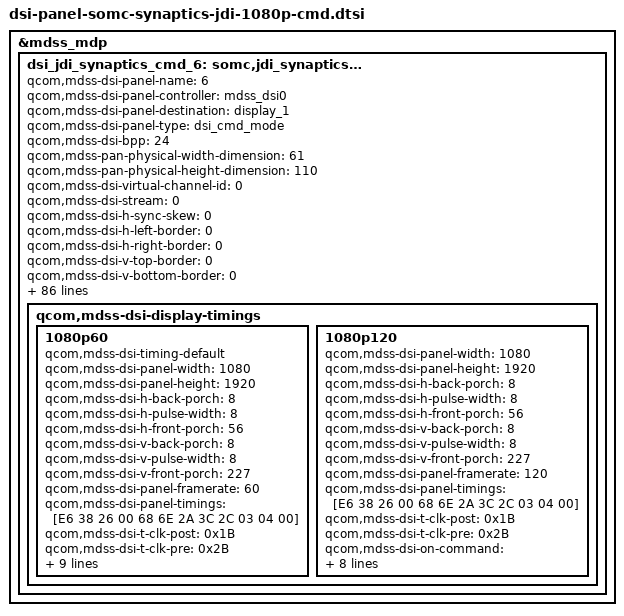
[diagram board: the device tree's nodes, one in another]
/* Copyright (c) 2016, The Linux Foundation. All rights reserved.
 *
 * This program is free software; you can redistribute it and/or modify
 * it under the terms of the GNU General Public License version 2 and
 * only version 2 as published by the Free Software Foundation.
 *
 * This program is distributed in the hope that it will be useful,
 * but WITHOUT ANY WARRANTY; without even the implied warranty of
 * MERCHANTABILITY or FITNESS FOR A PARTICULAR PURPOSE.  See the
 * GNU General Public License for more details.
 */
/*
 * Copyright (C) 2016 Sony Mobile Communications Inc.
 *
 * This program is free software; you can redistribute it and/or modify
 * it under the terms of the GNU General Public License version 2, as
 * published by the Free Software Foundation.
 */

&mdss_mdp {
	dsi_jdi_synaptics_cmd_6: somc,jdi_synaptics_cmd_6_panel {
		qcom,mdss-dsi-panel-name = "6";
		qcom,mdss-dsi-panel-controller = <&mdss_dsi0>;
		qcom,mdss-dsi-panel-destination = "display_1";
		qcom,mdss-dsi-panel-type = "dsi_cmd_mode";
		qcom,mdss-dsi-bpp = <24>;
		qcom,mdss-pan-physical-width-dimension = <61>;
		qcom,mdss-pan-physical-height-dimension = <110>;
		qcom,mdss-dsi-virtual-channel-id = <0>;
		qcom,mdss-dsi-stream = <0>;
		qcom,mdss-dsi-h-sync-skew = <0>;
		qcom,mdss-dsi-h-left-border = <0>;
		qcom,mdss-dsi-h-right-border = <0>;
		qcom,mdss-dsi-v-top-border = <0>;
		qcom,mdss-dsi-v-bottom-border = <0>;
		qcom,mdss-dsi-underflow-color = <0x0>;
		qcom,mdss-dsi-border-color = <0>;
		qcom,mdss-dsi-h-sync-pulse = <1>;
		qcom,mdss-dsi-traffic-mode = "non_burst_sync_event";
		qcom,mdss-dsi-bllp-eof-power-mode;
		qcom,mdss-dsi-bllp-power-mode;
		qcom,mdss-dsi-dma-trigger = "trigger_sw";
		qcom,mdss-dsi-mdp-trigger = "none";
		qcom,mdss-dsi-tx-eot-append;
		qcom,mdss-dsi-off-command = [
				39 01 00 00 14 00 01 28
				39 01 00 00 50 00 01 10];
		qcom,mdss-dsi-off-command-state = "dsi_hs_mode";
		qcom,mdss-dsi-te-pin-select = <1>;
		qcom,mdss-dsi-wr-mem-start = <0x2c>;
		qcom,mdss-dsi-wr-mem-continue = <0x3c>;
		qcom,mdss-dsi-te-dcs-command = <1>;
		qcom,mdss-dsi-te-check-enable;
		qcom,mdss-dsi-te-using-te-pin;
		qcom,mdss-dsi-lane-0-state;
		qcom,mdss-dsi-lane-1-state;
		qcom,mdss-dsi-lane-2-state;
		qcom,mdss-dsi-lane-3-state;
		qcom,mdss-dsi-lp11-init;
		qcom,mdss-dsi-bl-min-level = <1>;
		qcom,mdss-dsi-bl-max-level = <4095>;
		qcom,mdss-brightness-max-level = <255>;
		qcom,mdss-dsi-bl-pmic-control-type = "bl_ctrl_wled";

		somc,qpnp-lab-max-precharge-time = <300>;
		somc,qpnp-lab-soft-start = <800>;
		somc,qpnp-lab-pull-down-enable;
		somc,qpnp-lab-full-pull-down;
		somc,qpnp-ibb-pull-down-enable;
		somc,qpnp-ibb-full-pull-down;
		somc,lcd-id = <0>;
		somc,lcd-id-adc = <353000 653000>;
		somc,pw-on-rst-seq = <0 10>, <1 16>, <0 7>, <1 16>;
		somc,pw-off-rst-b-seq = <0 11>;
		somc,pw-wait-after-on-vdd = <0>;
		somc,pw-wait-after-on-vddio = <1>;
		somc,pw-wait-after-on-vsp = <1>;
		somc,pw-wait-after-on-vsn = <0>;
		somc,pw-wait-after-off-vdd = <0>;
		somc,pw-wait-after-off-vddio = <1>;
		somc,pw-wait-after-off-vsp = <10>;
		somc,pw-wait-after-off-vsn = <10>;
		somc,pw-wait-after-on-touch-avdd = <0>;
		somc,pw-wait-after-on-touch-vddio = <0>;
		somc,pw-wait-after-on-touch-reset = <0>;
		somc,pw-wait-after-on-touch-reset-first = <90>;
		somc,pw-wait-after-on-touch-int-n = <10>;
		somc,pw-wait-after-off-touch-avdd = <0>;
		somc,pw-wait-after-off-touch-vddio = <0>;
		somc,pw-wait-after-off-touch-reset = <5>;
		somc,pw-wait-after-off-touch-int-n = <0>;
		somc,pw-down-period = <100>;
		somc,ewu-wait-after-touch-reset = <40>;
		somc,mdss-dsi-disp-on-in-hs = <0>;
		somc,mdss-dsi-wait-time-before-post-on-cmd = <0>;

		somc,change-fps-enable;
		somc,change-fps-panel-type = "hybrid_incell_type";
		somc,change-fps-panel-mode = "dynamic_mode";
		somc,change-fps-command =
				[29 01 00 00 00 00 02 B0 04
				 29 01 00 00 00 00 02 D6 01
				 29 01 00 00 00 00 08 C2 01 07 80 04 00 04 F0];
		somc,driver-ic-rtn = <83>;
		somc,driver-ic-vdisp = <1920>;
		somc,driver-ic-vtouch = <6818000>;
		somc,driver-ic-mclk = <61539>;
		somc,change-fps-send-pos = <2 4>;
		somc,change-fps-send-byte = <4>;
		somc,change-fps-porch-mask-pos = <3>;
		somc,change-fps-porch-mask = <0xF0>;
		somc,mdss-dsi-pcc-enable;
		somc,panel-colormgr-pcc-prof-avail;
		somc,mdss-dsi-u-rev = <0 8>;
		somc,mdss-dsi-v-rev = <0 8>;
		somc,mdss-dsi-uv-command = [06 01 00 00 00 00 01 DA
			06 01 00 00 00 00 01 DB];
		somc,mdss-dsi-uv-param-type = <4>;
		somc,mdss-dsi-pcc-table-size = <226>;
		somc,mdss-dsi-pcc-table = <
				0x00 0x01 0x38 0x3B 0x38 0x3B 0x8000 0x8000 0x8000
				0x00 0x02 0x34 0x37 0x38 0x3B 0x8000 0x8000 0x8000
				0x00 0x03 0x30 0x33 0x38 0x3B 0x8000 0x8000 0x8000
				0x00 0x04 0x2C 0x2F 0x38 0x3B 0x8000 0x8000 0x8000
				0x00 0x05 0x28 0x2B 0x38 0x3B 0x8000 0x8000 0x8000
				0x00 0x06 0x24 0x27 0x38 0x3B 0x8000 0x8000 0x8000
				0x00 0x07 0x20 0x23 0x38 0x3B 0x8000 0x8000 0x8000
				0x00 0x08 0x1C 0x1F 0x38 0x3B 0x8000 0x8000 0x8000
				0x00 0x09 0x18 0x1B 0x38 0x3B 0x8000 0x8000 0x8000
				0x00 0x0A 0x14 0x17 0x38 0x3B 0x8000 0x8000 0x8000
				0x00 0x0B 0x10 0x13 0x38 0x3B 0x8000 0x8000 0x8000
				0x00 0x0C 0x0C 0x0F 0x38 0x3B 0x8000 0x8000 0x8000
				0x00 0x0D 0x08 0x0B 0x38 0x3B 0x8000 0x8000 0x8000
				0x00 0x0E 0x04 0x07 0x38 0x3B 0x8000 0x8000 0x8000
				0x00 0x0F 0x00 0x03 0x38 0x3B 0x8000 0x8000 0x8000
				0x00 0x10 0x38 0x3B 0x34 0x37 0x8000 0x8000 0x8000
				0x00 0x11 0x34 0x37 0x34 0x37 0x8000 0x8000 0x8000
				0x00 0x12 0x30 0x33 0x34 0x37 0x8000 0x8000 0x8000
				0x00 0x13 0x2C 0x2F 0x34 0x37 0x8000 0x8000 0x8000
				0x00 0x14 0x28 0x2B 0x34 0x37 0x8000 0x8000 0x8000
				0x00 0x15 0x24 0x27 0x34 0x37 0x8000 0x8000 0x8000
				0x00 0x16 0x20 0x23 0x34 0x37 0x8000 0x8000 0x8000
				0x00 0x17 0x1C 0x1F 0x34 0x37 0x8000 0x8000 0x8000
				0x00 0x18 0x18 0x1B 0x34 0x37 0x8000 0x8000 0x8000
				0x00 0x19 0x14 0x17 0x34 0x37 0x8000 0x8000 0x8000
				0x00 0x1A 0x10 0x13 0x34 0x37 0x8000 0x8000 0x8000
				0x00 0x1B 0x0C 0x0F 0x34 0x37 0x8000 0x8000 0x8000
				0x00 0x1C 0x08 0x0B 0x34 0x37 0x8000 0x8000 0x8000
				0x00 0x1D 0x04 0x07 0x34 0x37 0x8000 0x8000 0x8000
				0x00 0x1E 0x00 0x03 0x34 0x37 0x8000 0x8000 0x8000
				0x00 0x1F 0x38 0x3B 0x30 0x33 0x8000 0x8000 0x8000
				0x00 0x20 0x34 0x37 0x30 0x33 0x8000 0x8000 0x8000
				0x00 0x21 0x30 0x33 0x30 0x33 0x5500 0x6C80 0x8000
				0x00 0x22 0x2C 0x2F 0x30 0x33 0x5880 0x6C80 0x8000
				0x00 0x23 0x28 0x2B 0x30 0x33 0x5B80 0x6C00 0x8000
				0x00 0x24 0x24 0x27 0x30 0x33 0x5E00 0x6B80 0x8000
				0x00 0x25 0x20 0x23 0x30 0x33 0x6100 0x6B80 0x8000
				0x00 0x26 0x1C 0x1F 0x30 0x33 0x6400 0x6B00 0x8000
				0x00 0x27 0x18 0x1B 0x30 0x33 0x6680 0x6B00 0x8000
				0x00 0x28 0x14 0x17 0x30 0x33 0x6980 0x6B00 0x8000
				0x00 0x29 0x10 0x13 0x30 0x33 0x6D00 0x6A80 0x8000
				0x00 0x2A 0x0C 0x0F 0x30 0x33 0x7080 0x6A80 0x8000
				0x00 0x2B 0x08 0x0B 0x30 0x33 0x7500 0x6A80 0x8000
				0x00 0x2C 0x04 0x07 0x30 0x33 0x8000 0x8000 0x8000
				0x00 0x2D 0x00 0x03 0x30 0x33 0x8000 0x8000 0x8000
				0x00 0x2E 0x38 0x3B 0x2C 0x2F 0x8000 0x8000 0x8000
				0x00 0x2F 0x34 0x37 0x2C 0x2F 0x8000 0x8000 0x8000
				0x00 0x30 0x30 0x33 0x2C 0x2F 0x5B80 0x7180 0x8000
				0x00 0x31 0x2C 0x2F 0x2C 0x2F 0x5D80 0x7100 0x8000
				0x00 0x32 0x28 0x2B 0x2C 0x2F 0x6080 0x7080 0x8000
				0x00 0x33 0x24 0x27 0x2C 0x2F 0x6300 0x7000 0x8000
				0x00 0x34 0x20 0x23 0x2C 0x2F 0x6580 0x6F80 0x8000
				0x00 0x35 0x1C 0x1F 0x2C 0x2F 0x6800 0x6F80 0x8000
				0x00 0x36 0x18 0x1B 0x2C 0x2F 0x6B00 0x6F00 0x8000
				0x00 0x37 0x14 0x17 0x2C 0x2F 0x6E00 0x6F00 0x8000
				0x00 0x38 0x10 0x13 0x2C 0x2F 0x7180 0x6E80 0x8000
				0x00 0x39 0x0C 0x0F 0x2C 0x2F 0x7580 0x6E00 0x8000
				0x00 0x3A 0x08 0x0B 0x2C 0x2F 0x7880 0x6E00 0x8000
				0x00 0x3B 0x04 0x07 0x2C 0x2F 0x8000 0x8000 0x8000
				0x00 0x3C 0x00 0x03 0x2C 0x2F 0x8000 0x8000 0x8000
				0x00 0x3D 0x38 0x3B 0x28 0x2B 0x8000 0x8000 0x8000
				0x00 0x3E 0x34 0x37 0x28 0x2B 0x8000 0x8000 0x8000
				0x00 0x3F 0x30 0x33 0x28 0x2B 0x6000 0x7580 0x8000
				0x00 0x40 0x2C 0x2F 0x28 0x2B 0x6280 0x7500 0x8000
				0x00 0x41 0x28 0x2B 0x28 0x2B 0x6480 0x7480 0x8000
				0x00 0x42 0x24 0x27 0x28 0x2B 0x6700 0x7400 0x8000
				0x00 0x43 0x20 0x23 0x28 0x2B 0x6980 0x7380 0x8000
				0x00 0x44 0x1C 0x1F 0x28 0x2B 0x6C80 0x7380 0x8000
				0x00 0x45 0x18 0x1B 0x28 0x2B 0x6F80 0x7300 0x8000
				0x00 0x46 0x14 0x17 0x28 0x2B 0x7300 0x7280 0x8000
				0x00 0x47 0x10 0x13 0x28 0x2B 0x7600 0x7200 0x8000
				0x00 0x48 0x0C 0x0F 0x28 0x2B 0x7900 0x7200 0x8000
				0x00 0x49 0x08 0x0B 0x28 0x2B 0x7D00 0x7180 0x8000
				0x00 0x4A 0x04 0x07 0x28 0x2B 0x8000 0x8000 0x8000
				0x00 0x4B 0x00 0x03 0x28 0x2B 0x8000 0x8000 0x8000
				0x00 0x4C 0x38 0x3B 0x24 0x27 0x8000 0x8000 0x8000
				0x00 0x4D 0x34 0x37 0x24 0x27 0x8000 0x8000 0x8000
				0x00 0x4E 0x30 0x33 0x24 0x27 0x6400 0x7A00 0x8000
				0x00 0x4F 0x2C 0x2F 0x24 0x27 0x6580 0x7980 0x8000
				0x00 0x50 0x28 0x2B 0x24 0x27 0x6800 0x7880 0x8000
				0x00 0x51 0x24 0x27 0x24 0x27 0x6400 0x6F10 0x8000
				0x00 0x52 0x20 0x23 0x24 0x27 0x8000 0x7C90 0x6EDB
				0x00 0x53 0x1C 0x1F 0x24 0x27 0x7780 0x7A10 0x8000
				0x00 0x54 0x18 0x1B 0x24 0x27 0x5E00 0x6A10 0x8000
				0x00 0x55 0x14 0x17 0x24 0x27 0x7680 0x7600 0x8000
				0x00 0x56 0x10 0x13 0x24 0x27 0x7980 0x7580 0x8000
				0x00 0x57 0x0C 0x0F 0x24 0x27 0x7D00 0x7500 0x8000
				0x00 0x58 0x08 0x0B 0x24 0x27 0x8000 0x7500 0x8000
				0x00 0x59 0x04 0x07 0x24 0x27 0x8000 0x8000 0x8000
				0x00 0x5A 0x00 0x03 0x24 0x27 0x8000 0x8000 0x8000
				0x00 0x5B 0x38 0x3B 0x20 0x23 0x8000 0x8000 0x8000
				0x00 0x5C 0x34 0x37 0x20 0x23 0x8000 0x8000 0x8000
				0x00 0x5D 0x30 0x33 0x20 0x23 0x6700 0x7E00 0x8000
				0x00 0x5E 0x2C 0x2F 0x20 0x23 0x6980 0x7D00 0x8000
				0x00 0x5F 0x28 0x2B 0x20 0x23 0x6C00 0x7C80 0x8000
				0x00 0x60 0x24 0x27 0x20 0x23 0x6E80 0x7C00 0x8000
				0x00 0x61 0x20 0x23 0x20 0x23 0x7100 0x7B80 0x8000
				0x00 0x62 0x1C 0x1F 0x20 0x23 0x7480 0x7A80 0x8000
				0x00 0x63 0x18 0x1B 0x20 0x23 0x7700 0x7A00 0x8000
				0x00 0x64 0x14 0x17 0x20 0x23 0x7A00 0x7980 0x8000
				0x00 0x65 0x10 0x13 0x20 0x23 0x7D00 0x7900 0x8000
				0x00 0x66 0x0C 0x0F 0x20 0x23 0x8000 0x7880 0x8000
				0x00 0x67 0x08 0x0B 0x20 0x23 0x8000 0x7480 0x7D00
				0x00 0x68 0x04 0x07 0x20 0x23 0x8000 0x8000 0x8000
				0x00 0x69 0x00 0x03 0x20 0x23 0x8000 0x8000 0x8000
				0x00 0x6A 0x38 0x3B 0x1C 0x1F 0x8000 0x8000 0x8000
				0x00 0x6B 0x34 0x37 0x1C 0x1F 0x8000 0x8000 0x8000
				0x00 0x6C 0x30 0x33 0x1C 0x1F 0x6900 0x8000 0x7F00
				0x00 0x6D 0x2C 0x2F 0x1C 0x1F 0x6C00 0x8000 0x7F80
				0x00 0x6E 0x28 0x2B 0x1C 0x1F 0x6F80 0x8000 0x8000
				0x00 0x6F 0x24 0x27 0x1C 0x1F 0x7200 0x7F80 0x8000
				0x00 0x70 0x20 0x23 0x1C 0x1F 0x7500 0x7F00 0x8000
				0x00 0x71 0x1C 0x1F 0x1C 0x1F 0x7780 0x7E00 0x8000
				0x00 0x72 0x18 0x1B 0x1C 0x1F 0x7A80 0x7D80 0x8000
				0x00 0x73 0x14 0x17 0x1C 0x1F 0x7D00 0x7D00 0x8000
				0x00 0x74 0x10 0x13 0x1C 0x1F 0x8000 0x7C80 0x8000
				0x00 0x75 0x0C 0x0F 0x1C 0x1F 0x8000 0x7880 0x7D00
				0x00 0x76 0x08 0x0B 0x1C 0x1F 0x8000 0x7400 0x7900
				0x00 0x77 0x04 0x07 0x1C 0x1F 0x8000 0x8000 0x8000
				0x00 0x78 0x00 0x03 0x1C 0x1F 0x8000 0x8000 0x8000
				0x00 0x79 0x38 0x3B 0x18 0x1B 0x8000 0x8000 0x8000
				0x00 0x7A 0x34 0x37 0x18 0x1B 0x8000 0x8000 0x8000
				0x00 0x7B 0x30 0x33 0x18 0x1B 0x6800 0x8000 0x7B00
				0x00 0x7C 0x2C 0x2F 0x18 0x1B 0x6B80 0x8000 0x7C00
				0x00 0x7D 0x28 0x2B 0x18 0x1B 0x6E80 0x8000 0x7D00
				0x00 0x7E 0x24 0x27 0x18 0x1B 0x7200 0x8000 0x7D80
				0x00 0x7F 0x20 0x23 0x18 0x1B 0x7600 0x8000 0x7E80
				0x00 0x80 0x1C 0x1F 0x18 0x1B 0x7980 0x8000 0x7F00
				0x00 0x81 0x18 0x1B 0x18 0x1B 0x7D00 0x8000 0x7F80
				0x00 0x82 0x14 0x17 0x18 0x1B 0x8000 0x8000 0x8000
				0x00 0x83 0x10 0x13 0x18 0x1B 0x8000 0x7C80 0x7D80
				0x00 0x84 0x0C 0x0F 0x18 0x1B 0x8000 0x7800 0x7980
				0x00 0x85 0x08 0x0B 0x18 0x1B 0x8000 0x7380 0x7600
				0x00 0x86 0x04 0x07 0x18 0x1B 0x8000 0x8000 0x8000
				0x00 0x87 0x00 0x03 0x18 0x1B 0x8000 0x8000 0x8000
				0x00 0x88 0x38 0x3B 0x14 0x17 0x8000 0x8000 0x8000
				0x00 0x89 0x34 0x37 0x14 0x17 0x8000 0x8000 0x8000
				0x00 0x8A 0x30 0x33 0x14 0x17 0x6700 0x8000 0x7780
				0x00 0x8B 0x2C 0x2F 0x14 0x17 0x6A80 0x8000 0x7880
				0x00 0x8C 0x28 0x2B 0x14 0x17 0x6E00 0x8000 0x7980
				0x00 0x8D 0x24 0x27 0x14 0x17 0x7180 0x8000 0x7A00
				0x00 0x8E 0x20 0x23 0x14 0x17 0x7580 0x8000 0x7B00
				0x00 0x8F 0x1C 0x1F 0x14 0x17 0x7900 0x8000 0x7C00
				0x00 0x90 0x18 0x1B 0x14 0x17 0x7C80 0x8000 0x7C80
				0x00 0x91 0x14 0x17 0x14 0x17 0x8000 0x8000 0x7D80
				0x00 0x92 0x10 0x13 0x14 0x17 0x8000 0x7C80 0x7A00
				0x00 0x93 0x0C 0x0F 0x14 0x17 0x8000 0x7800 0x7700
				0x00 0x94 0x08 0x0B 0x14 0x17 0x8000 0x7380 0x7380
				0x00 0x95 0x04 0x07 0x14 0x17 0x8000 0x8000 0x8000
				0x00 0x96 0x00 0x03 0x14 0x17 0x8000 0x8000 0x8000
				0x00 0x97 0x38 0x3B 0x10 0x13 0x8000 0x8000 0x8000
				0x00 0x98 0x34 0x37 0x10 0x13 0x8000 0x8000 0x8000
				0x00 0x99 0x30 0x33 0x10 0x13 0x6600 0x8000 0x7480
				0x00 0x9A 0x2C 0x2F 0x10 0x13 0x6980 0x8000 0x7580
				0x00 0x9B 0x28 0x2B 0x10 0x13 0x6D00 0x8000 0x7680
				0x00 0x9C 0x24 0x27 0x10 0x13 0x7100 0x8000 0x7700
				0x00 0x9D 0x20 0x23 0x10 0x13 0x7500 0x8000 0x7800
				0x00 0x9E 0x1C 0x1F 0x10 0x13 0x7880 0x8000 0x7880
				0x00 0x9F 0x18 0x1B 0x10 0x13 0x7C80 0x8000 0x7980
				0x00 0xA0 0x14 0x17 0x10 0x13 0x8000 0x8000 0x7A00
				0x00 0xA1 0x10 0x13 0x10 0x13 0x8000 0x7C80 0x7780
				0x00 0xA2 0x0C 0x0F 0x10 0x13 0x8000 0x7800 0x7400
				0x00 0xA3 0x08 0x0B 0x10 0x13 0x8000 0x7300 0x7000
				0x00 0xA4 0x04 0x07 0x10 0x13 0x8000 0x8000 0x8000
				0x00 0xA5 0x00 0x03 0x10 0x13 0x8000 0x8000 0x8000
				0x00 0xA6 0x38 0x3B 0x0C 0x0F 0x8000 0x8000 0x8000
				0x00 0xA7 0x34 0x37 0x0C 0x0F 0x8000 0x8000 0x8000
				0x00 0xA8 0x30 0x33 0x0C 0x0F 0x6580 0x8000 0x7100
				0x00 0xA9 0x2C 0x2F 0x0C 0x0F 0x6880 0x8000 0x7200
				0x00 0xAA 0x28 0x2B 0x0C 0x0F 0x6C80 0x8000 0x7380
				0x00 0xAB 0x24 0x27 0x0C 0x0F 0x7080 0x8000 0x7480
				0x00 0xAC 0x20 0x23 0x0C 0x0F 0x7480 0x8000 0x7580
				0x00 0xAD 0x1C 0x1F 0x0C 0x0F 0x7800 0x8000 0x7600
				0x00 0xAE 0x18 0x1B 0x0C 0x0F 0x7C00 0x8000 0x7700
				0x00 0xAF 0x14 0x17 0x0C 0x0F 0x8000 0x8000 0x7780
				0x00 0xB0 0x10 0x13 0x0C 0x0F 0x8000 0x7C80 0x7500
				0x00 0xB1 0x0C 0x0F 0x0C 0x0F 0x8000 0x7780 0x7180
				0x00 0xB2 0x08 0x0B 0x0C 0x0F 0x8000 0x7280 0x6D80
				0x00 0xB3 0x04 0x07 0x0C 0x0F 0x8000 0x8000 0x8000
				0x00 0xB4 0x00 0x03 0x0C 0x0F 0x8000 0x8000 0x8000
				0x00 0xB5 0x38 0x3B 0x08 0x0B 0x8000 0x8000 0x8000
				0x00 0xB6 0x34 0x37 0x08 0x0B 0x8000 0x8000 0x8000
				0x00 0xB7 0x30 0x33 0x08 0x0B 0x6480 0x8000 0x6E00
				0x00 0xB8 0x2C 0x2F 0x08 0x0B 0x6780 0x8000 0x6F80
				0x00 0xB9 0x28 0x2B 0x08 0x0B 0x6B80 0x8000 0x7080
				0x00 0xBA 0x24 0x27 0x08 0x0B 0x6F80 0x8000 0x7180
				0x00 0xBB 0x20 0x23 0x08 0x0B 0x7400 0x8000 0x7300
				0x00 0xBC 0x1C 0x1F 0x08 0x0B 0x7800 0x8000 0x7380
				0x00 0xBD 0x18 0x1B 0x08 0x0B 0x7C00 0x8000 0x7480
				0x00 0xBE 0x14 0x17 0x08 0x0B 0x7F80 0x8000 0x7580
				0x00 0xBF 0x10 0x13 0x08 0x0B 0x8000 0x7C80 0x7300
				0x00 0xC0 0x0C 0x0F 0x08 0x0B 0x8000 0x7780 0x6F00
				0x00 0xC1 0x08 0x0B 0x08 0x0B 0x8000 0x7200 0x6B80
				0x00 0xC2 0x04 0x07 0x08 0x0B 0x8000 0x8000 0x8000
				0x00 0xC3 0x00 0x03 0x08 0x0B 0x8000 0x8000 0x8000
				0x00 0xC4 0x38 0x3B 0x04 0x07 0x8000 0x8000 0x8000
				0x00 0xC5 0x34 0x37 0x04 0x07 0x8000 0x8000 0x8000
				0x00 0xC6 0x30 0x33 0x04 0x07 0x8000 0x8000 0x8000
				0x00 0xC7 0x2C 0x2F 0x04 0x07 0x8000 0x8000 0x8000
				0x00 0xC8 0x28 0x2B 0x04 0x07 0x8000 0x8000 0x8000
				0x00 0xC9 0x24 0x27 0x04 0x07 0x8000 0x8000 0x8000
				0x00 0xCA 0x20 0x23 0x04 0x07 0x8000 0x8000 0x8000
				0x00 0xCB 0x1C 0x1F 0x04 0x07 0x8000 0x8000 0x8000
				0x00 0xCC 0x18 0x1B 0x04 0x07 0x8000 0x8000 0x8000
				0x00 0xCD 0x14 0x17 0x04 0x07 0x8000 0x8000 0x8000
				0x00 0xCE 0x10 0x13 0x04 0x07 0x8000 0x8000 0x8000
				0x00 0xCF 0x0C 0x0F 0x04 0x07 0x8000 0x8000 0x8000
				0x00 0xD0 0x08 0x0B 0x04 0x07 0x8000 0x8000 0x8000
				0x00 0xD1 0x04 0x07 0x04 0x07 0x8000 0x8000 0x8000
				0x00 0xD2 0x00 0x03 0x04 0x07 0x8000 0x8000 0x8000
				0x00 0xD3 0x38 0x3B 0x00 0x03 0x8000 0x8000 0x8000
				0x00 0xD4 0x34 0x37 0x00 0x03 0x8000 0x8000 0x8000
				0x00 0xD5 0x30 0x33 0x00 0x03 0x8000 0x8000 0x8000
				0x00 0xD6 0x2C 0x2F 0x00 0x03 0x8000 0x8000 0x8000
				0x00 0xD7 0x28 0x2B 0x00 0x03 0x8000 0x8000 0x8000
				0x00 0xD8 0x24 0x27 0x00 0x03 0x8000 0x8000 0x8000
				0x00 0xD9 0x20 0x23 0x00 0x03 0x8000 0x8000 0x8000
				0x00 0xDA 0x1C 0x1F 0x00 0x03 0x8000 0x8000 0x8000
				0x00 0xDB 0x18 0x1B 0x00 0x03 0x8000 0x8000 0x8000
				0x00 0xDC 0x14 0x17 0x00 0x03 0x8000 0x8000 0x8000
				0x00 0xDD 0x10 0x13 0x00 0x03 0x8000 0x8000 0x8000
				0x00 0xDE 0x0C 0x0F 0x00 0x03 0x8000 0x8000 0x8000
				0x00 0xDF 0x08 0x0B 0x00 0x03 0x8000 0x8000 0x8000
				0x00 0xE0 0x04 0x07 0x00 0x03 0x8000 0x8000 0x8000
				0x00 0xE1 0x00 0x03 0x00 0x03 0x8000 0x8000 0x8000
				0xFF 0x00 0x0E 0x38 0x0C 0x2F 0x8000 0x8000 0x8000>;

		qcom,dynamic-mode-switch-enabled;
		qcom,dynamic-mode-switch-type = "dynamic-resolution-switch-immediate";
		qcom,mdss-dsi-display-timings {
			1080p60 {
				qcom,mdss-dsi-timing-default;
				qcom,mdss-dsi-panel-width = <1080>;
				qcom,mdss-dsi-panel-height = <1920>;
				qcom,mdss-dsi-h-back-porch = <8>;
				qcom,mdss-dsi-h-pulse-width = <8>;
				qcom,mdss-dsi-h-front-porch = <56>;
				qcom,mdss-dsi-v-back-porch = <8>;
				qcom,mdss-dsi-v-pulse-width = <8>;
				qcom,mdss-dsi-v-front-porch = <227>;
				qcom,mdss-dsi-panel-framerate = <60>;
				qcom,mdss-dsi-panel-timings = [E6 38 26 00 68 6E 2A 3C 2C 03 04 00];
				qcom,mdss-dsi-t-clk-post = <0x1B>;
				qcom,mdss-dsi-t-clk-pre = <0x2B>;
				qcom,mdss-dsi-on-command = [
						29 01 00 00 00 00 02 B0 00
						29 01 00 00 00 00 02 D6 01
						29 01 00 00 00 00 03 C4 70 03
						29 01 00 00 00 00 1B ED 27 31 2F 13 00 6A 99 03 17 91 F2 00 00 03 14 17 3F 14 12 26 23 00 20 00 00 57
						29 01 00 00 00 00 1B EE 13 61 5F 09 00 6A 99 03 00 01 B2 00 00 03 00 00 33 14 12 00 21 00 20 00 00 57
						29 01 00 00 00 00 1B EF 27 31 2F 13 00 00 00 00 00 00 00 00 00 03 14 17 0F 14 00 00 20 00 00 00 00 A6
						29 01 00 00 00 00 1B F0 E3 07 73 DF 00 00 00 00 00 00 00 00 E0 E3 00 00 03 14 00 00 20 00 00 00 00 A7
						39 01 00 00 00 00 02 35 00
						39 01 00 00 00 00 02 36 00
						39 01 00 00 00 00 02 3A 77
						39 01 00 00 00 00 05 2A 00 00 04 37
						39 01 00 00 00 00 05 2B 00 00 07 7F
						39 01 00 00 00 00 03 44 00 00
						39 01 00 00 78 00 01 11];
				qcom,mdss-dsi-post-panel-on-command = [
						39 01 00 00 00 00 01 29];
				qcom,mdss-dsi-on-command-state = "dsi_lp_mode";

				qcom,mdss-tear-check-sync-init-val = <1920>;
				qcom,mdss-tear-check-start-pos = <1920>;
				qcom,mdss-tear-check-rd-ptr-trigger-intr = <1921>;

				qcom,mdss-dsi-panel-clockrate = <899000000>;
			};

			1080p120 {
				qcom,mdss-dsi-panel-width = <1080>;
				qcom,mdss-dsi-panel-height = <1920>;
				qcom,mdss-dsi-h-back-porch = <8>;
				qcom,mdss-dsi-h-pulse-width = <8>;
				qcom,mdss-dsi-h-front-porch = <56>;
				qcom,mdss-dsi-v-back-porch = <8>;
				qcom,mdss-dsi-v-pulse-width = <8>;
				qcom,mdss-dsi-v-front-porch = <227>;
				qcom,mdss-dsi-panel-framerate = <120>;
				qcom,mdss-dsi-panel-timings = [E6 38 26 00 68 6E 2A 3C 2C 03 04 00];
				qcom,mdss-dsi-t-clk-post = <0x1B>;
				qcom,mdss-dsi-t-clk-pre = <0x2B>;
				qcom,mdss-dsi-on-command = [
						29 01 00 00 00 00 02 B0 00
						29 01 00 00 00 00 02 D6 01
						29 01 00 00 00 00 03 C4 70 03
						29 01 00 00 00 00 1B ED 27 31 2F 13 00 6A 99 03 17 91 F2 00 00 03 14 17 3F 14 12 26 23 00 20 00 00 57
						29 01 00 00 00 00 1B EE 13 61 5F 09 00 6A 99 03 00 01 B2 00 00 03 00 00 33 14 12 00 21 00 20 00 00 57
						29 01 00 00 00 00 1B EF 27 31 2F 13 00 00 00 00 00 00 00 00 00 03 14 17 0F 14 00 00 20 00 00 00 00 A6
						29 01 00 00 00 00 1B F0 E3 07 73 DF 00 00 00 00 00 00 00 00 E0 E3 00 00 03 14 00 00 20 00 00 00 00 A7
						39 01 00 00 00 00 02 35 00
						39 01 00 00 00 00 02 36 00
						39 01 00 00 00 00 02 3A 77
						39 01 00 00 00 00 05 2A 00 00 04 37
						39 01 00 00 00 00 05 2B 00 00 07 7F
						39 01 00 00 00 00 03 44 00 00
						39 01 00 00 78 00 01 11];
				qcom,mdss-dsi-post-panel-on-command = [
						39 01 00 00 00 00 01 29];
				qcom,mdss-dsi-on-command-state = "dsi_lp_mode";

				qcom,mdss-tear-check-sync-init-val = <1920>;
				qcom,mdss-tear-check-start-pos = <1920>;
				qcom,mdss-tear-check-rd-ptr-trigger-intr = <1921>;

				qcom,mdss-dsi-panel-clockrate = <899000000>;
			};
		};
	};
};
